# M058SAN_v1 register map
File version: 1.0
Registers are 32-bit, read-write, reset 0x0 unless marked. A register's access mark holds for its fields unless they carry their own. Offsets are from the block's base; [hi:lo] are bit positions.

## WWDT — WWDT Register Map
Base 0x40004100
0x00 WWDTRLD wo — Window Watchdog Timer Reload Counter Register
  [31:0] WWDTRLD — WWDT Reload Counter Register. Writing 0x00005AA5 to this register will reload the Window Watchdog Timer counter value to 0x3F. Note: Software can only write WWDTRLD to reload WWDT counter value when current WWDT counter value between 0 and WINCMP. If software writes WWDTRLD when current WWDT counter value larger than WINCMP, WWDT reset signal will generate immediately.
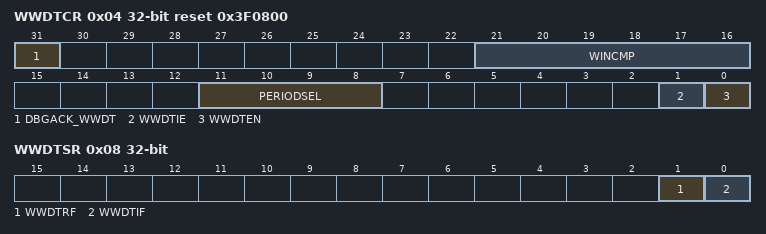
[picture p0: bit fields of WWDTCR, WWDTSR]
0x04 WWDTCR reset 0x3F0800 — Window Watchdog Timer Control Register
  [31] DBGACK_WWDT — ICE debug mode acknowledge Disable
    0=WWDT counter stopped if system is in Debug mode; 1=WWDT still counted even system is in Debug mode
  [21:16] WINCMP — WWDT Window Compare Register. Set this register to adjust the valid reload window. Note: Software can only write WWDTRLD to reload WWDT counter value when current WWDT counter value between 0 and WINCMP. If Software writes WWDTRLD when current WWDT counter value larger than WINCMP, WWDT reset signal will generate immediately.
  [11:8] PERIODSEL — WWDT Pre-scale Period Select
  [1] WWDTIE — WWDT Interrupt Enable. Setting this bit to enable the Window Watchdog Timer time-out interrupt function.
    0=WWDT time-out interrupt function Disabled if WWDTIF (WWDTSR[0] WWDT compare match interrupt flag) is 1; 1=WWDT time-out interrupt function Enabled if WWDTIF (WWDTSR[0] WWDT compare match interrupt flag) is 1
  [0] WWDTEN — WWDT Enable. Set this bit to enable Window Watchdog Timer counter counting.
    0=Window Watchdog Timer counter is stopped; 1=Window Watchdog Timer counter is starting counting
0x08 WWDTSR — Window Watchdog Timer Status Register
  [1] WWDTRF — WWDT Reset Flag. When WWDT counter counts down to 0 or writes WWDTRLD during current WWDT counter value larger than WINCMP, chip will be reset and this bit is set to 1. This bit will be cleared to 0 by writing 1 to itself.
  [0] WWDTIF — WWDT Compare Match Interrupt Flag. When current WWDT counter value matches to WWCMP, this bit is set to 1. This bit will be cleared by writing 1 to itself.
0x0C WWDTCVR ro reset 0x3F — Window Watchdog Timer Counter Value Register
  [5:0] WWDTCVAL — WWDT Counter Value. This register reflects the current WWDT counter value and this register is read only

## FMC — FMC Register Map
Base 0x5000C000
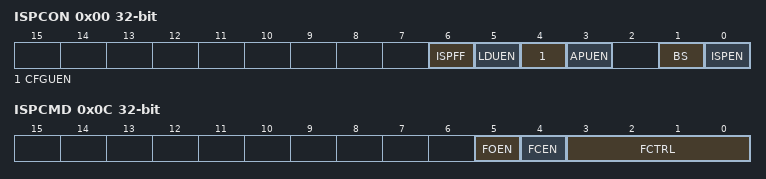
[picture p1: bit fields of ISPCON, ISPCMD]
0x00 ISPCON — ISP Control Register
  [6] ISPFF — ISP Fail Flag (write-protection bit). This bit is set by hardware when a triggered ISP meets any of the following conditions: (1) APROM writes to itself if APUEN is set to 0 (2) LDROM writes to itself if LDUEN is set to 0 (3) CONFIG is erased/programmed if CFGUEN is set to 0 (4) Destination address is illegal, such as over an available range. Write 1 to clear.
  [5] LDUEN — LDROM Update Enable (write-protection bit). LDROM update enable bit.
    0=LDROM cannot be updated; 1=LDROM can be updated
  [4] CFGUEN — Config Update Enable (write-protected). Writing this bit to 1 enables s/w to update Configure value by ISP procedure regardless of program code is running in APROM or LDROM.
    0=Config update disable; 1=Config update enable
  [3] APUEN — APROM Update Enable (write-protected)
    0=APROM cannot be updated when the chip runs in APROM; 1=APROM can be updated when the chip runs in APROM
  [1] BS — Boot Select (write-protected). Set/clear this bit to select next booting from LDROM/APROM, respectively. This bit also functions as MCU booting status flag, which can be used to check where MCU booted from. This bit is initiated with the inversed value of CBS in Config0 after power-on reset; It keeps the same value at other reset.
    0=boot from APROM; 1=boot from LDROM
  [0] ISPEN — ISP Enable (write-protected). ISP function enable bit. Set this bit to enable ISP function.
    0=Disable ISP function; 1=Enable ISP function
0x04 ISPADR — ISP Address Register
  [31:0] ISPADR — ISP Address. M058SLAN equips with a 8k x 32 embedded flash, it supports word program only. ISPADR[1:0] must be kept 2'b00 for ISP operation.
0x08 ISPDAT — ISP Data Register
  [31:0] ISPDAT — ISP Data. Write data to this register before ISP program operation. Read data from this register after ISP read operation
0x0C ISPCMD — ISP Command Register
  [5] FOEN — ISP Command
  [4] FCEN — ISP Command
  [3:0] FCTRL — ISP Command
0x10 ISPTRG — ISP Trigger Register
  [0] ISPGO — ISP start trigger(write-protected). Write 1 to start ISP operation and this bit will be cleared to 0 by hardware automatically when ISP operation is finish.
    0=ISP done; 1=ISP is on going
0x14 DFBADR ro reset 0x1F000 — Data Flash Base Address
  [31:0] DFBADR — Data Flash Base Address. This register indicates data flash start address. It is a read only register. For M058SLAN, the data flash size is 4KB and it start address is fixed at 0x0001_F000 by hardware internally.
0x18 FATCON reset 0x80 — Flash Access Time Control Register
  [4] LFOM — Low Frequency Optimization Mode (Write-protection Bit). When chip operation frequency is lower than 25 MHz, chip can work more efficiently by setting this bit to 1
    0=Low frequency optimization mode Disabled; 1=Low frequency optimization mode Enabled
